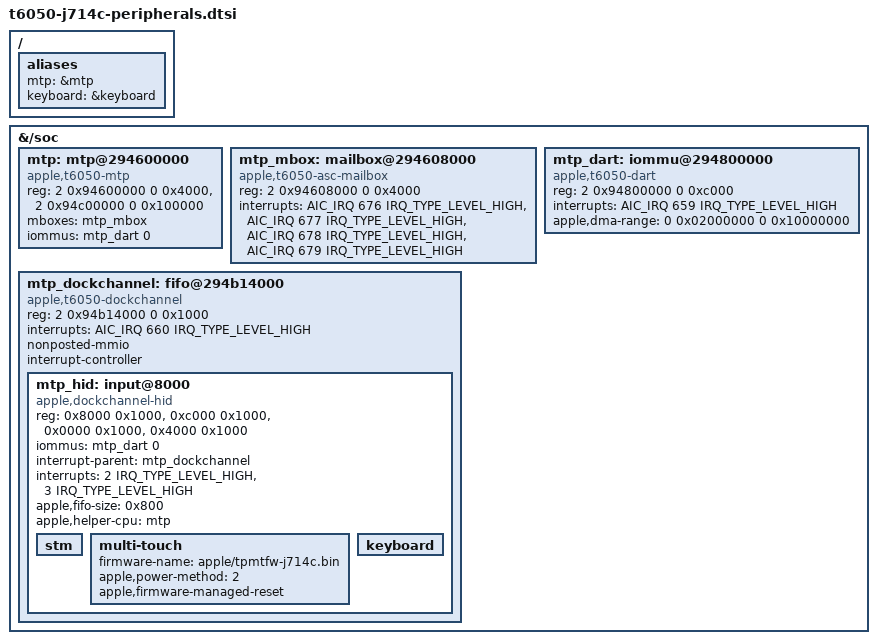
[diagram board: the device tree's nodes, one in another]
// SPDX-License-Identifier: GPL-2.0+ OR MIT
/*
 * T6050 j714c: built-in keyboard and trackpad, MTP over DockChannel.
 * Generated by tools/asahi/mtp_dt_from_adt.py from an ADT of this board; the same
 * derivation reproduces the J813 nodes. The SRAM window (asc + 0x600000) is not
 * in the ADT; it is the J813 offset. The MTP ASC and DART carry no power or clock
 * gates in the ADT, so no power-domains are listed: the boot firmware keeps the
 * block powered, as on J813.
 * The trackpad firmware is the user's own (apple/tpmtfw-j714c.bin); none is shipped.
 * Power method 2 with firmware-owned reset follows J813, the same MTP generation.
 */
#include <dt-bindings/interrupt-controller/apple-aic.h>
#include <dt-bindings/interrupt-controller/irq.h>

/ {
	aliases {
		mtp = &mtp;
		keyboard = &keyboard;
	};
};

&{/soc} {
	mtp: mtp@294600000 {
		compatible = "apple,t6050-mtp", "apple,t6050-rtk-helper-asc4",
			     "apple,mtp", "apple,rtk-helper-asc4";
		/* The second region is firmware SRAM, not the ASC control window. */
		reg = <2 0x94600000 0 0x4000>,
		      <2 0x94c00000 0 0x100000>;
		reg-names = "asc", "sram";
		mboxes = <&mtp_mbox>;
		iommus = <&mtp_dart 0>;
	};

	mtp_mbox: mailbox@294608000 {
		compatible = "apple,t6050-asc-mailbox", "apple,asc-mailbox-v4";
		reg = <2 0x94608000 0 0x4000>;
		interrupts = <AIC_IRQ 676 IRQ_TYPE_LEVEL_HIGH>,
			     <AIC_IRQ 677 IRQ_TYPE_LEVEL_HIGH>,
			     <AIC_IRQ 678 IRQ_TYPE_LEVEL_HIGH>,
			     <AIC_IRQ 679 IRQ_TYPE_LEVEL_HIGH>;
		interrupt-names = "send-empty", "send-not-empty", "recv-empty", "recv-not-empty";
		#mbox-cells = <0>;
	};

	mtp_dart: iommu@294800000 {
		compatible = "apple,t6050-dart", "apple,t8110-dart";
		reg = <2 0x94800000 0 0xc000>;
		interrupts = <AIC_IRQ 659 IRQ_TYPE_LEVEL_HIGH>;
		#iommu-cells = <1>;
		/* Keep host allocations clear of firmware's low IOVA mappings. */
		apple,dma-range = <0 0x02000000 0 0x10000000>;
	};

	mtp_dockchannel: fifo@294b14000 {
		compatible = "apple,t6050-dockchannel", "apple,dockchannel";
		reg = <2 0x94b14000 0 0x1000>;
		reg-names = "irq";
		interrupts = <AIC_IRQ 660 IRQ_TYPE_LEVEL_HIGH>;
		ranges = <0 2 0x94b28000 0x20000>;
		nonposted-mmio;
		#address-cells = <1>;
		#size-cells = <1>;
		interrupt-controller;
		#interrupt-cells = <2>;

		mtp_hid: input@8000 {
			compatible = "apple,dockchannel-hid";
			reg = <0x8000 0x1000>, <0xc000 0x1000>,
			      <0x0000 0x1000>, <0x4000 0x1000>;
			reg-names = "config", "data", "rmt-config", "rmt-data";
			iommus = <&mtp_dart 0>;
			interrupt-parent = <&mtp_dockchannel>;
			interrupts = <2 IRQ_TYPE_LEVEL_HIGH>, <3 IRQ_TYPE_LEVEL_HIGH>;
			interrupt-names = "tx", "rx";
			apple,fifo-size = <0x800>;
			apple,helper-cpu = <&mtp>;

			stm { };

			multi-touch {
				firmware-name = "apple/tpmtfw-j714c.bin";
				apple,power-method = <2>;
				apple,firmware-managed-reset;
			};

			/* Layout is filled by the loader using this machine's own data. */
			keyboard: keyboard { };
		};
	};
};
